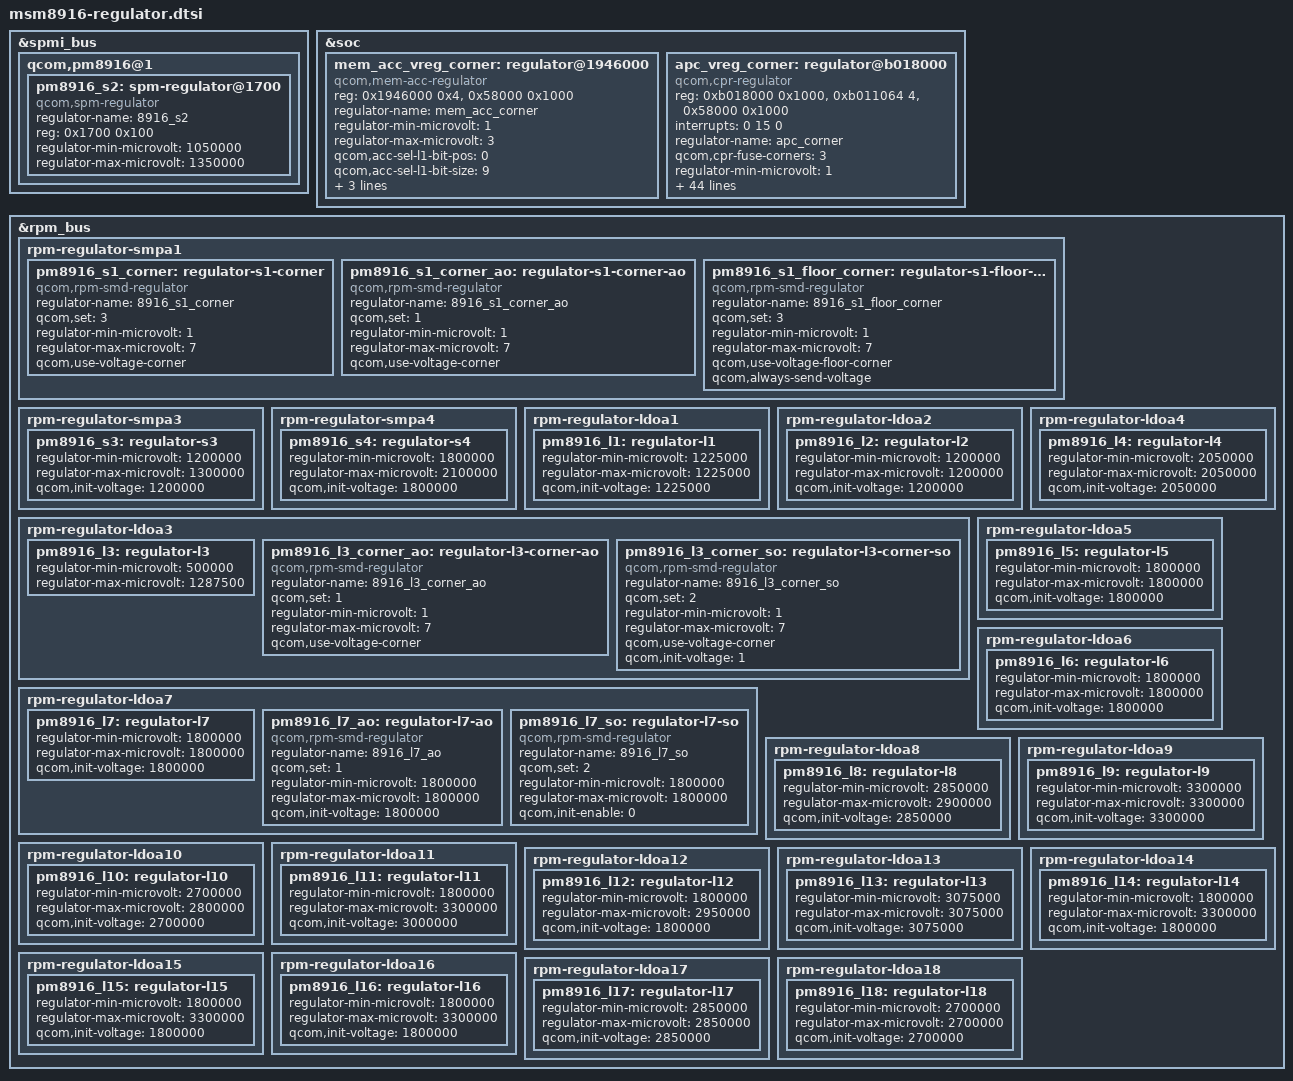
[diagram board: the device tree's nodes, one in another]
/* Copyright (c) 2013-2015, The Linux Foundation. All rights reserved.
 *
 * This program is free software; you can redistribute it and/or modify
 * it under the terms of the GNU General Public License version 2 and
 * only version 2 as published by the Free Software Foundation.
 *
 * This program is distributed in the hope that it will be useful,
 * but WITHOUT ANY WARRANTY; without even the implied warranty of
 * MERCHANTABILITY or FITNESS FOR A PARTICULAR PURPOSE.  See the
 * GNU General Public License for more details.
 */

/* SPM controlled regulators */
&spmi_bus {
	qcom,pm8916@1 {
		pm8916_s2: spm-regulator@1700 {
			compatible = "qcom,spm-regulator";
			regulator-name = "8916_s2";
			reg = <0x1700 0x100>;
			regulator-min-microvolt = <1050000>;
			regulator-max-microvolt = <1350000>;
		};
	};
};

/* CPR controlled regulator */

&soc {
	mem_acc_vreg_corner: regulator@1946000 {
		compatible = "qcom,mem-acc-regulator";
		reg = <0x1946000 0x4>, <0x58000 0x1000>;
		reg-names = "acc-sel-l1", "efuse_addr";
		regulator-name = "mem_acc_corner";
		regulator-min-microvolt = <1>;
		regulator-max-microvolt = <3>;

		qcom,acc-sel-l1-bit-pos = <0>;
		qcom,acc-sel-l1-bit-size = <9>;
		qcom,corner-acc-map = <0x0 0x100 0x101>;

		qcom,override-acc-fuse-sel = <0 52 1 1 0>;
		qcom,override-corner-acc-map = <0x0 0x100 0x100>;
	};

	apc_vreg_corner: regulator@b018000 {
		compatible = "qcom,cpr-regulator";
		reg = <0xb018000 0x1000>, <0xb011064 4>, <0x58000 0x1000>;
		reg-names = "rbcpr", "rbcpr_clk", "efuse_addr";
		interrupts = <0 15 0>;
		regulator-name = "apc_corner";
		qcom,cpr-fuse-corners = <3>;
		regulator-min-microvolt = <1>;
		regulator-max-microvolt = <9>;

		qcom,cpr-voltage-ceiling = <1050000 1150000 1350000>;
		qcom,cpr-voltage-floor = <1050000 1050000 1162500>;
		vdd-apc-supply = <&pm8916_s2>;

		qcom,vdd-mx-corner-map = <4 5 7>;
		qcom,vdd-mx-vmin-method = <4>;
		vdd-mx-supply = <&pm8916_l3_corner_ao>;
		qcom,vdd-mx-vmax = <7>;

		mem-acc-supply = <&mem_acc_vreg_corner>;

		qcom,cpr-ref-clk = <19200>;
		qcom,cpr-timer-delay = <5000>;
		qcom,cpr-timer-cons-up = <0>;
		qcom,cpr-timer-cons-down = <2>;
		qcom,cpr-irq-line = <0>;
		qcom,cpr-step-quotient = <26>;
		qcom,cpr-up-threshold = <0>;
		qcom,cpr-down-threshold = <2>;
		qcom,cpr-idle-clocks = <15>;
		qcom,cpr-gcnt-time = <1>;
		qcom,vdd-apc-step-up-limit = <1>;
		qcom,vdd-apc-step-down-limit = <1>;
		qcom,cpr-apc-volt-step = <12500>;

		qcom,cpr-fuse-row = <27 0>;
		qcom,cpr-fuse-target-quot = <42 24 6>;
		qcom,cpr-fuse-ro-sel = <54 54 54>;
		qcom,cpr-fuse-bp-cpr-disable = <57>;
		qcom,cpr-fuse-init-voltage =
					<27 36 6 0>,
					<27 18 6 0>,
					<27 0 6 0>;
		qcom,cpr-init-voltage-ref = <1050000 1150000 1350000>;
		qcom,cpr-init-voltage-step = <10000>;
		qcom,cpr-corner-map = <1 1 2 2 3 3 3 3 3>;
		qcom,cpr-corner-frequency-map =
					<1 200000000>,
					<2 400000000>,
					<3 533330000>,
					<4 800000000>,
					<5 998400000>,
					<6 1094400000>,
					<7 1152000000>,
					<8 1209600000>,
					<9 1363200000>;
		qcom,speed-bin-fuse-sel = <1 34 3 0>;
		qcom,pvs-version-fuse-sel = <0 55 2 0>;
		qcom,cpr-speed-bin-max-corners =
					<0 0 2 4 8>,
					<0 1 2 4 7>,
					<2 0 2 4 9>;
		qcom,cpr-quot-adjust-scaling-factor-max = <650>;
		qcom,cpr-enable;
	};
};


/* RPM controlled regulators */
&rpm_bus {

	/* PM8916 S1 VDD_CX supply */
	rpm-regulator-smpa1 {
		status = "okay";
		pm8916_s1_corner: regulator-s1-corner {
			compatible = "qcom,rpm-smd-regulator";
			regulator-name = "8916_s1_corner";
			qcom,set = <3>;
			regulator-min-microvolt = <1>;
			regulator-max-microvolt = <7>;
			qcom,use-voltage-corner;
		};
		pm8916_s1_corner_ao: regulator-s1-corner-ao {
			compatible = "qcom,rpm-smd-regulator";
			regulator-name = "8916_s1_corner_ao";
			qcom,set = <1>;
			regulator-min-microvolt = <1>;
			regulator-max-microvolt = <7>;
			qcom,use-voltage-corner;
		};
		pm8916_s1_floor_corner: regulator-s1-floor-corner {
			compatible = "qcom,rpm-smd-regulator";
			regulator-name = "8916_s1_floor_corner";
			qcom,set = <3>;
			regulator-min-microvolt = <1>;
			regulator-max-microvolt = <7>;
			qcom,use-voltage-floor-corner;
			qcom,always-send-voltage;
		};
	};

	rpm-regulator-smpa3 {
		status = "okay";
		pm8916_s3: regulator-s3 {
			regulator-min-microvolt = <1200000>;
			regulator-max-microvolt = <1300000>;
			qcom,init-voltage = <1200000>;
			status = "okay";
		};
	};

	rpm-regulator-smpa4 {
		status = "okay";
		pm8916_s4: regulator-s4 {
			regulator-min-microvolt = <1800000>;
			regulator-max-microvolt = <2100000>;
			qcom,init-voltage = <1800000>;
			status = "okay";
		};
	};

	rpm-regulator-ldoa1 {
		status = "okay";
		pm8916_l1: regulator-l1 {
			regulator-min-microvolt = <1225000>;
			regulator-max-microvolt = <1225000>;
			qcom,init-voltage = <1225000>;
			status = "okay";
		};
	};

	rpm-regulator-ldoa2 {
		status = "okay";
		pm8916_l2: regulator-l2 {
			regulator-min-microvolt = <1200000>;
			regulator-max-microvolt = <1200000>;
			qcom,init-voltage = <1200000>;
			status = "okay";
		};
	};

	/* PM8916 L3 VDD_MX supply */
	rpm-regulator-ldoa3 {
		status = "okay";
		pm8916_l3: regulator-l3 {
			regulator-min-microvolt = <500000>;
			regulator-max-microvolt = <1287500>;
			status = "okay";
		};

		pm8916_l3_corner_ao: regulator-l3-corner-ao {
			compatible = "qcom,rpm-smd-regulator";
			regulator-name = "8916_l3_corner_ao";
			qcom,set = <1>;
			regulator-min-microvolt = <1>;
			regulator-max-microvolt = <7>;
			qcom,use-voltage-corner;
		};

		pm8916_l3_corner_so: regulator-l3-corner-so {
			compatible = "qcom,rpm-smd-regulator";
			regulator-name = "8916_l3_corner_so";
			qcom,set = <2>;
			regulator-min-microvolt = <1>;
			regulator-max-microvolt = <7>;
			qcom,use-voltage-corner;
			qcom,init-voltage = <1>;
		};
	};

	rpm-regulator-ldoa4 {
		status = "okay";
		pm8916_l4: regulator-l4 {
			regulator-min-microvolt = <2050000>;
			regulator-max-microvolt = <2050000>;
			qcom,init-voltage = <2050000>;
			status = "okay";
		};
	};

	rpm-regulator-ldoa5 {
		status = "okay";
		pm8916_l5: regulator-l5 {
			regulator-min-microvolt = <1800000>;
			regulator-max-microvolt = <1800000>;
			qcom,init-voltage = <1800000>;
			status = "okay";
		};
	};

	rpm-regulator-ldoa6 {
		status = "okay";
		pm8916_l6: regulator-l6 {
			regulator-min-microvolt = <1800000>;
			regulator-max-microvolt = <1800000>;
			qcom,init-voltage = <1800000>;
			status = "okay";
		};
	};

	rpm-regulator-ldoa7 {
		status = "okay";
		pm8916_l7: regulator-l7 {
			regulator-min-microvolt = <1800000>;
			regulator-max-microvolt = <1800000>;
			qcom,init-voltage = <1800000>;
			status = "okay";
		};

		pm8916_l7_ao: regulator-l7-ao {
			compatible = "qcom,rpm-smd-regulator";
			regulator-name = "8916_l7_ao";
			qcom,set = <1>;
			regulator-min-microvolt = <1800000>;
			regulator-max-microvolt = <1800000>;
			qcom,init-voltage = <1800000>;
		};

		pm8916_l7_so: regulator-l7-so {
			compatible = "qcom,rpm-smd-regulator";
			regulator-name = "8916_l7_so";
			qcom,set = <2>;
			regulator-min-microvolt = <1800000>;
			regulator-max-microvolt = <1800000>;
			qcom,init-enable = <0>;
		};
	};

	rpm-regulator-ldoa8 {
		status = "okay";
		pm8916_l8: regulator-l8 {
			regulator-min-microvolt = <2850000>;
			regulator-max-microvolt = <2900000>;
			qcom,init-voltage = <2850000>;
			status = "okay";
		};
	};

	rpm-regulator-ldoa9 {
		status = "okay";
		pm8916_l9: regulator-l9 {
			regulator-min-microvolt = <3300000>;
			regulator-max-microvolt = <3300000>;
			qcom,init-voltage = <3300000>;
			status = "okay";
		};
	};

	rpm-regulator-ldoa10 {
		status = "okay";
		pm8916_l10: regulator-l10 {
			regulator-min-microvolt = <2700000>;
			regulator-max-microvolt = <2800000>;
			qcom,init-voltage = <2700000>;
			status = "okay";
		};
	};

	rpm-regulator-ldoa11 {
		status = "okay";
		pm8916_l11: regulator-l11 {
			regulator-min-microvolt = <1800000>;
			regulator-max-microvolt = <3300000>;
			qcom,init-voltage = <3000000>;
			status = "okay";
		};
	};

	rpm-regulator-ldoa12 {
		status = "okay";
		pm8916_l12: regulator-l12 {
			regulator-min-microvolt = <1800000>;
			regulator-max-microvolt = <2950000>;
			qcom,init-voltage = <1800000>;
			status = "okay";
		};
	};

	rpm-regulator-ldoa13 {
		status = "okay";
		pm8916_l13: regulator-l13 {
			regulator-min-microvolt = <3075000>;
			regulator-max-microvolt = <3075000>;
			qcom,init-voltage = <3075000>;
			status = "okay";
		};
	};

	rpm-regulator-ldoa14 {
		status = "okay";
		pm8916_l14: regulator-l14 {
			regulator-min-microvolt = <1800000>;
			regulator-max-microvolt = <3300000>;
			qcom,init-voltage = <1800000>;
			status = "okay";
		};
	};

	rpm-regulator-ldoa15 {
		status = "okay";
		pm8916_l15: regulator-l15 {
			regulator-min-microvolt = <1800000>;
			regulator-max-microvolt = <3300000>;
			qcom,init-voltage = <1800000>;
			status = "okay";
		};
	};

	rpm-regulator-ldoa16 {
		status = "okay";
		pm8916_l16: regulator-l16 {
			regulator-min-microvolt = <1800000>;
			regulator-max-microvolt = <3300000>;
			qcom,init-voltage = <1800000>;
			status = "okay";
		};
	};

	rpm-regulator-ldoa17 {
		status = "okay";
		pm8916_l17: regulator-l17 {
			regulator-min-microvolt = <2850000>;
			regulator-max-microvolt = <2850000>;
			qcom,init-voltage = <2850000>;
			status = "okay";
		};
	};

	rpm-regulator-ldoa18 {
		status = "okay";
		pm8916_l18: regulator-l18 {
			regulator-min-microvolt = <2700000>;
			regulator-max-microvolt = <2700000>;
			qcom,init-voltage = <2700000>;
			status = "okay";
		};
	};
};
